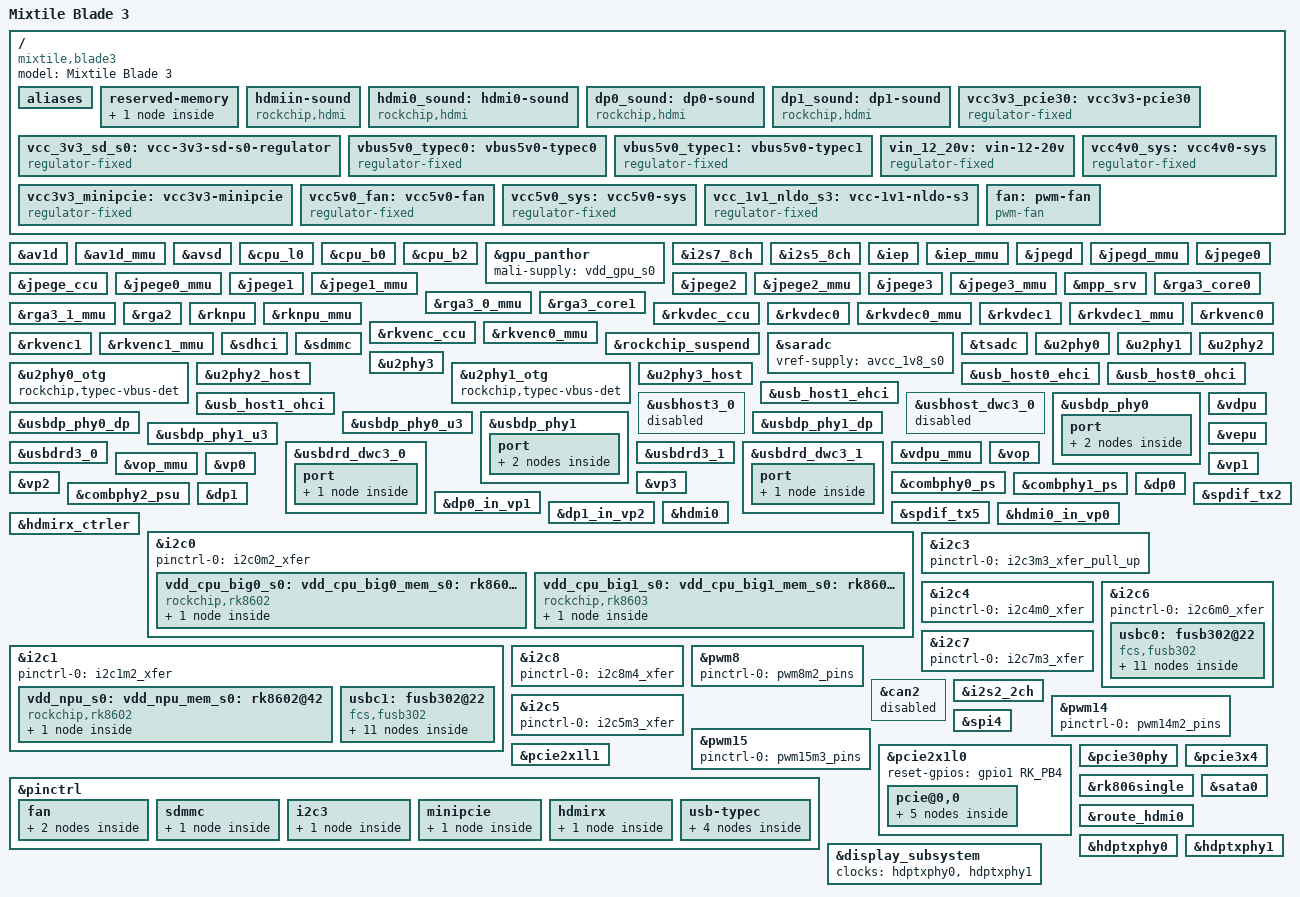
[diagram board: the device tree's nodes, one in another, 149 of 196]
// SPDX-License-Identifier: (GPL-2.0+ OR MIT)
/*
 * Copyright (c) 2026 Mixtile Limited
 *
 */

/dts-v1/;

#include <dt-bindings/gpio/gpio.h>
#include <dt-bindings/pwm/pwm.h>
#include <dt-bindings/pinctrl/rockchip.h>
#include <dt-bindings/input/rk-input.h>
#include <dt-bindings/display/drm_mipi_dsi.h>
#include <dt-bindings/display/rockchip_vop.h>
#include <dt-bindings/sensor-dev.h>

#include "dt-bindings/usb/pd.h"
#include "rk3588.dtsi"
#include "rk3588-rk806-single.dtsi"
#include "rk3588-linux.dtsi"

/ {
	model = "Mixtile Blade 3";
	compatible = "mixtile,blade3", "rockchip,rk3588";
	/delete-node/ chosen;

	aliases {
		ethernet0 = &rtl_eth0;
		ethernet1 = &rtl_eth1;
	};

	/* If hdmirx node is disabled, delete the reserved-memory node here. */
	reserved-memory {
		#address-cells = <2>;
		#size-cells = <2>;
		ranges;

		/* Reserve 256MB memory for hdmirx-controller@fdee0000 */
		cma {
			compatible = "shared-dma-pool";
			reusable;
			size = <0x0 (256 * 0x100000)>;
			linux,cma-default;
		};
	};

	hdmiin-sound {
		compatible = "rockchip,hdmi";
		rockchip,mclk-fs = <128>;
		rockchip,format = "i2s";
		rockchip,bitclock-master = <&hdmirx_ctrler>;
		rockchip,frame-master = <&hdmirx_ctrler>;
		rockchip,card-name = "rockchip-hdmiin";
		rockchip,cpu = <&i2s7_8ch>;
		rockchip,codec = <&hdmirx_ctrler 0>;
		rockchip,jack-det;
	};

	hdmi0_sound: hdmi0-sound {
		status = "okay";
		compatible = "rockchip,hdmi";
		rockchip,mclk-fs = <128>;
		rockchip,card-name = "rockchip-hdmi0";
		rockchip,cpu = <&i2s5_8ch>;
		rockchip,codec = <&hdmi0>;
		rockchip,jack-det;
	};

	dp0_sound: dp0-sound {
		status = "okay";
		compatible = "rockchip,hdmi";
		rockchip,card-name = "rockchip-dp0";
		rockchip,mclk-fs = <512>;
		rockchip,cpu = <&spdif_tx2>;
		rockchip,codec = <&dp0 1>;
		rockchip,jack-det;
	};

	dp1_sound: dp1-sound {
		status = "okay";
		compatible = "rockchip,hdmi";
		rockchip,card-name = "rockchip-dp1";
		rockchip,mclk-fs = <512>;
		rockchip,cpu = <&spdif_tx5>;
		rockchip,codec = <&dp1 1>;
		rockchip,jack-det;
	};

	vcc3v3_pcie30: vcc3v3-pcie30 {
		compatible = "regulator-fixed";
		regulator-name = "vcc3v3_pcie30";
		regulator-min-microvolt = <3300000>;
		regulator-max-microvolt = <3300000>;
		enable-active-high;
		gpio = <&gpio1 RK_PB2 GPIO_ACTIVE_HIGH>;
		startup-delay-us = <5000>;
		vin-supply = <&vcc4v0_sys>;
	};

	vcc_3v3_sd_s0: vcc-3v3-sd-s0-regulator {
		compatible = "regulator-fixed";
		regulator-name = "vcc_3v3_sd_s0";
		regulator-min-microvolt = <3300000>;
		regulator-max-microvolt = <3300000>;
		gpio = <&gpio0 RK_PB7 GPIO_ACTIVE_LOW>;
		startup-delay-us = <2000>;
		pinctrl-names = "default";
		pinctrl-0 = <&sd_s0_pwr>;
		vin-supply = <&vcc_3v3_s3>;
	};

	vbus5v0_typec0: vbus5v0-typec0 {
		compatible = "regulator-fixed";
		regulator-name = "vbus5v0_typec0";
		regulator-min-microvolt = <5000000>;
		regulator-max-microvolt = <5000000>;
		enable-active-high;
		gpio = <&gpio4 RK_PB0 GPIO_ACTIVE_HIGH>;
		pinctrl-names = "default";
		pinctrl-0 = <&typec5v_pwren0>;
		vin-supply = <&vcc5v0_sys>;
	};

	vbus5v0_typec1: vbus5v0-typec1 {
		compatible = "regulator-fixed";
		regulator-name = "vbus5v0_typec1";
		regulator-min-microvolt = <5000000>;
		regulator-max-microvolt = <5000000>;
		enable-active-high;
		gpio = <&gpio4 RK_PA3 GPIO_ACTIVE_HIGH>;
		pinctrl-names = "default";
		pinctrl-0 = <&typec5v_pwren1>;
		vin-supply = <&vcc5v0_sys>;
	};

	vin_12_20v: vin-12-20v {
		compatible = "regulator-fixed";
		regulator-name = "vin_12_20v";
		regulator-boot-on;
		regulator-always-on;
	};

	vcc4v0_sys: vcc4v0-sys {
		compatible = "regulator-fixed";
		regulator-name = "vcc4v0_sys";
		regulator-boot-on;
		regulator-always-on;
		regulator-min-microvolt = <4000000>;
		regulator-max-microvolt = <4000000>;
		vin-supply = <&vin_12_20v>;
	};

	vcc3v3_minipcie: vcc3v3-minipcie {
		compatible = "regulator-fixed";
		regulator-name = "vcc3v3_minipcie";
		regulator-boot-on;
		regulator-always-on;
		regulator-min-microvolt = <3300000>;
		regulator-max-microvolt = <3300000>;
		enable-active-high;
		gpio = <&gpio3 RK_PC6 GPIO_ACTIVE_HIGH>;
		startup-delay-us = <5000>;
		pinctrl-names = "default";
		pinctrl-0 = <&minipcie_pwren>;
		vin-supply = <&vin_12_20v>;
	};

	vcc5v0_fan: vcc5v0-fan {
		compatible = "regulator-fixed";
		regulator-name = "vcc5v0_fan";
		regulator-min-microvolt = <5000000>;
		regulator-max-microvolt = <5000000>;
		enable-active-high;
		gpio = <&gpio3 RK_PC0 GPIO_ACTIVE_HIGH>;
		pinctrl-names = "default";
		pinctrl-0 = <&fan_pwren>;
		vin-supply = <&vcc5v0_sys>;
	};

	vcc5v0_sys: vcc5v0-sys {
		compatible = "regulator-fixed";
		regulator-name = "vcc5v0_sys";
		regulator-boot-on;
		regulator-always-on;
		regulator-min-microvolt = <5000000>;
		regulator-max-microvolt = <5000000>;
		vin-supply = <&vin_12_20v>;
	};

	vcc_1v1_nldo_s3: vcc-1v1-nldo-s3 {
		compatible = "regulator-fixed";
		regulator-name = "vcc_1v1_nldo_s3";
		regulator-boot-on;
		regulator-always-on;
		regulator-min-microvolt = <1100000>;
		regulator-max-microvolt = <1100000>;
		vin-supply = <&vcc4v0_sys>;
	};

	fan: pwm-fan {
		compatible = "pwm-fan";
		interrupt-parent = <&gpio3>;
		interrupts = <RK_PB1 IRQ_TYPE_EDGE_FALLING>;
		pulses-per-revolution = <2>;
		#cooling-cells = <2>;
		cooling-levels = <0 35 70 100 125 150>;
		pwms = <&pwm8 0 40000 0>; /* 40000 meant for Noctua */
		pinctrl-names = "default";
		pinctrl-0 = <&fan_tach>; /* for the pull-up on the tacho input */
		fan-supply = <&vcc5v0_fan>;
		rockchip,temp-trips = <
			30000   1
			45000   2
			50000   3
			55000   4
			60000   5
		>;
	};
};

&av1d {
	status = "okay";
};

&av1d_mmu {
	status = "okay";
};

&avsd {
	status = "okay";
};

&cpu_l0 {
	cpu-supply = <&vdd_cpu_lit_s0>;
	mem-supply = <&vdd_cpu_lit_mem_s0>;
};

&cpu_b0 {
	cpu-supply = <&vdd_cpu_big0_s0>;
	mem-supply = <&vdd_cpu_big0_mem_s0>;
};

&cpu_b2 {
	cpu-supply = <&vdd_cpu_big1_s0>;
	mem-supply = <&vdd_cpu_big1_mem_s0>;
};

&gpu_panthor {
	mali-supply = <&vdd_gpu_s0>;
	status = "okay";
};

&i2s7_8ch {
	status = "okay";
};

&i2s5_8ch {
	status = "okay";
};

&iep {
	status = "okay";
};

&iep_mmu {
	status = "okay";
};

&jpegd {
	status = "okay";
};

&jpegd_mmu {
	status = "okay";
};

&jpege_ccu {
	status = "okay";
};

&jpege0 {
	status = "okay";
};

&jpege0_mmu {
	status = "okay";
};

&jpege1 {
	status = "okay";
};

&jpege1_mmu {
	status = "okay";
};

&jpege2 {
	status = "okay";
};

&jpege2_mmu {
	status = "okay";
};

&jpege3 {
	status = "okay";
};

&jpege3_mmu {
	status = "okay";
};

&mpp_srv {
	status = "okay";
};

&rga3_core0 {
	status = "okay";
};

&rga3_0_mmu {
	status = "okay";
};

&rga3_core1 {
	status = "okay";
};

&rga3_1_mmu {
	status = "okay";
};

&rga2 {
	status = "okay";
};

&rknpu {
	rknpu-supply = <&vdd_npu_s0>;
	mem-supply = <&vdd_npu_mem_s0>;
	status = "okay";
};

&rknpu_mmu {
	status = "okay";
};

&rkvdec_ccu {
	status = "okay";
};

&rkvdec0 {
	status = "okay";
};

&rkvdec0_mmu {
	status = "okay";
};

&rkvdec1 {
	status = "okay";
};

&rkvdec1_mmu {
	status = "okay";
};

&rkvenc_ccu {
	status = "okay";
};

&rkvenc0 {
	venc-supply = <&vdd_vdenc_s0>;
	mem-supply = <&vdd_vdenc_mem_s0>;
	status = "okay";
};

&rkvenc0_mmu {
	status = "okay";
};

&rkvenc1 {
	venc-supply = <&vdd_vdenc_s0>;
	mem-supply = <&vdd_vdenc_mem_s0>;
	status = "okay";
};

&rkvenc1_mmu {
	status = "okay";
};

&rockchip_suspend {
	status = "okay";
	rockchip,sleep-debug-en = <1>;
	rockchip,sleep-mode-config = <
		(0
		| RKPM_SLP_ARMOFF_DDRPD
		| RKPM_SLP_PMU_PMUALIVE_32K
		| RKPM_SLP_PMU_DIS_OSC
		)
	>;
};

&saradc {
	status = "okay";
	vref-supply = <&avcc_1v8_s0>;
};

&sdhci {
	bus-width = <8>;
	no-sdio;
	no-sd;
	non-removable;
	max-frequency = <200000000>;
	mmc-hs400-1_8v;
	mmc-hs400-enhanced-strobe;
	status = "okay";
};

&sdmmc {
	max-frequency = <150000000>;
	no-sdio;
	no-mmc;
	bus-width = <4>;
	cap-mmc-highspeed;
	cap-sd-highspeed;
	disable-wp;
	sd-uhs-sdr104;
	vmmc-supply = <&vcc_3v3_sd_s0>;
	vqmmc-supply = <&vccio_sd_s0>;
	status = "okay";
};

&tsadc {
	status = "okay";
};

&u2phy0 {
	status = "okay";
};

&u2phy1 {
	status = "okay";
};

&u2phy2 {
	status = "okay";
};

&u2phy3 {
	status = "okay";
};

&u2phy0_otg {
	status = "okay";
	rockchip,typec-vbus-det;
};

&u2phy1_otg {
	status = "okay";
	rockchip,typec-vbus-det;
};

&u2phy2_host {
	status = "okay";
};

&u2phy3_host {
	status = "okay";
};

&usb_host0_ehci {
	status = "okay";
};

&usb_host0_ohci {
	status = "okay";
};

&usb_host1_ehci {
	status = "okay";
};

&usb_host1_ohci {
	status = "okay";
};

&usbhost3_0 {
	status = "disabled";
};

&usbhost_dwc3_0 {
	status = "disabled";
};

&usbdp_phy0 {
	status = "okay";

	orientation-switch;
	svid = <0xff01>;
	sbu1-dc-gpios = <&gpio4 RK_PA6 GPIO_ACTIVE_HIGH>;
	sbu2-dc-gpios = <&gpio4 RK_PA7 GPIO_ACTIVE_HIGH>;

	port {
		#address-cells = <1>;
		#size-cells = <0>;
		usbdp_phy0_orientation_switch: endpoint@0 {
			reg = <0>;
			remote-endpoint = <&usbc0_orien_sw>;
		};

		usbdp_phy0_dp_altmode_mux: endpoint@1 {
			reg = <1>;
			remote-endpoint = <&dp0_altmode_mux>;
		};
	};
};

&usbdp_phy0_dp {
	status = "okay";
};

&usbdp_phy0_u3 {
	status = "okay";
};

&usbdp_phy1 {
	status = "okay";

	orientation-switch;
	svid = <0xff01>;
	sbu1-dc-gpios = <&gpio4 RK_PA4 GPIO_ACTIVE_HIGH>;
	sbu2-dc-gpios = <&gpio4 RK_PA5 GPIO_ACTIVE_HIGH>;

	port {
		#address-cells = <1>;
		#size-cells = <0>;
		usbdp_phy1_orientation_switch: endpoint@0 {
			reg = <0>;
			remote-endpoint = <&usbc1_orien_sw>;
		};

		usbdp_phy1_dp_altmode_mux: endpoint@1 {
			reg = <1>;
			remote-endpoint = <&dp1_altmode_mux>;
		};
	};
};

&usbdp_phy1_dp {
	status = "okay";
};

&usbdp_phy1_u3 {
	status = "okay";
};

&usbdrd3_0 {
	status = "okay";
};

&usbdrd_dwc3_0 {
	status = "okay";

	dr_mode = "otg";
	usb-role-switch;
	port {
		#address-cells = <1>;
		#size-cells = <0>;
		dwc3_0_role_switch: endpoint@0 {
			reg = <0>;
			remote-endpoint = <&usbc0_role_sw>;
		};
	};
};

&usbdrd3_1 {
	status = "okay";
};

&usbdrd_dwc3_1 {
	status = "okay";

	dr_mode = "otg";
	usb-role-switch;
	port {
		#address-cells = <1>;
		#size-cells = <0>;
		dwc3_1_role_switch: endpoint@0 {
			reg = <0>;
			remote-endpoint = <&usbc1_role_sw>;
		};
	};
};

&vdpu {
	status = "okay";
};

&vdpu_mmu {
	status = "okay";
};

&vepu {
	status = "okay";
};

&vop {
	assigned-clocks = <&cru ACLK_VOP>;
	assigned-clock-rates = <800000000>;
	vop-supply = <&vdd_log_s0>;
	status = "okay";
};

&vop_mmu {
	status = "okay";
};

/* vp0 & vp1 splice for 8K output */
&vp0 {
	rockchip,plane-mask = <(1 << ROCKCHIP_VOP2_CLUSTER0 | 1 << ROCKCHIP_VOP2_ESMART0)>;
	rockchip,primary-plane = <ROCKCHIP_VOP2_CLUSTER0>;
	cursor-win-id = <ROCKCHIP_VOP2_ESMART0>;
};

&vp1 {
	rockchip,plane-mask = <(1 << ROCKCHIP_VOP2_CLUSTER1 | 1 << ROCKCHIP_VOP2_ESMART1)>;
	rockchip,primary-plane = <ROCKCHIP_VOP2_CLUSTER1>;
	cursor-win-id = <ROCKCHIP_VOP2_ESMART1>;
};

&vp2 {
	rockchip,plane-mask = <(1 << ROCKCHIP_VOP2_CLUSTER2 | 1 << ROCKCHIP_VOP2_ESMART2)>;
	rockchip,primary-plane = <ROCKCHIP_VOP2_CLUSTER2>;
	cursor-win-id = <ROCKCHIP_VOP2_ESMART2>;
};

&vp3 {
	rockchip,plane-mask = <(1 << ROCKCHIP_VOP2_CLUSTER3 | 1 << ROCKCHIP_VOP2_ESMART3)>;
	rockchip,primary-plane = <ROCKCHIP_VOP2_CLUSTER3>;
	cursor-win-id = <ROCKCHIP_VOP2_ESMART3>;
};

&combphy0_ps {
	status = "okay";
};

&combphy1_ps {
	status = "okay";
};

&combphy2_psu {
	status = "okay";
};

&dp0 {
	status = "okay";
};

&dp0_in_vp1 {
	status = "okay";
};

&spdif_tx2 {
	status = "okay";
};

&dp1 {
	status = "okay";
};

&dp1_in_vp2 {
	status = "okay";
};

&spdif_tx5 {
	status = "okay";
};

&hdmi0 {
	enable-gpios = <&gpio4 RK_PB1 GPIO_ACTIVE_HIGH>;
	cec-enable;
	status = "okay";
};

&hdmi0_in_vp0 {
	status = "okay";
};

/* Should work with at least 128MB cma reserved above. */
&hdmirx_ctrler {
	status = "okay";
	#sound-dai-cells = <1>;
	/* Effective level used to trigger HPD: 0-low, 1-high */
	hpd-trigger-level = <1>;
	hdmirx-det-gpios = <&gpio1 RK_PD5 GPIO_ACTIVE_LOW>;
	pinctrl-0 = <&hdmim1_rx_cec &hdmim1_rx_hpdin &hdmim1_rx_scl &hdmim1_rx_sda &hdmirx_det>;
	pinctrl-names = "default";
};

&i2c0 {
	status = "okay";
	pinctrl-names = "default";
	pinctrl-0 = <&i2c0m2_xfer>;

	vdd_cpu_big0_s0: vdd_cpu_big0_mem_s0: rk8602@42 {
		compatible = "rockchip,rk8602";
		reg = <0x42>;
		vin-supply = <&vcc4v0_sys>;
		regulator-compatible = "rk860x-reg";
		regulator-name = "vdd_cpu_big0_s0";
		regulator-min-microvolt = <550000>;
		regulator-max-microvolt = <1050000>;
		regulator-ramp-delay = <2300>;
		rockchip,suspend-voltage-selector = <1>;
		regulator-boot-on;
		regulator-always-on;
		regulator-state-mem {
			regulator-off-in-suspend;
		};
	};

	vdd_cpu_big1_s0: vdd_cpu_big1_mem_s0: rk8603@43 {
		compatible = "rockchip,rk8603";
		reg = <0x43>;
		vin-supply = <&vcc4v0_sys>;
		regulator-compatible = "rk860x-reg";
		regulator-name = "vdd_cpu_big1_s0";
		regulator-min-microvolt = <550000>;
		regulator-max-microvolt = <1050000>;
		regulator-ramp-delay = <2300>;
		rockchip,suspend-voltage-selector = <1>;
		regulator-boot-on;
		regulator-always-on;
		regulator-state-mem {
			regulator-off-in-suspend;
		};
	};
};

&i2c1 {
	status = "okay";
	pinctrl-names = "default";
	pinctrl-0 = <&i2c1m2_xfer>;

	vdd_npu_s0: vdd_npu_mem_s0: rk8602@42 {
		compatible = "rockchip,rk8602";
		reg = <0x42>;
		vin-supply = <&vcc4v0_sys>;
		regulator-compatible = "rk860x-reg";
		regulator-name = "vdd_npu_s0";
		regulator-min-microvolt = <550000>;
		regulator-max-microvolt = <950000>;
		regulator-ramp-delay = <2300>;
		rockchip,suspend-voltage-selector = <1>;
		regulator-boot-on;
		regulator-always-on;
		regulator-state-mem {
			regulator-off-in-suspend;
		};
	};

	usbc1: fusb302@22 {
		compatible = "fcs,fusb302";
		reg = <0x22>;
		interrupt-parent = <&gpio0>;
		interrupts = <RK_PC6 IRQ_TYPE_LEVEL_LOW>;
		pinctrl-names = "default";
		pinctrl-0 = <&usbc1_int>;
		vbus-supply = <&vbus5v0_typec1>;
		status = "okay";

		ports {
			#address-cells = <1>;
			#size-cells = <0>;

			port@0 {
				reg = <0>;
				usbc1_role_sw: endpoint@0 {
					remote-endpoint = <&dwc3_1_role_switch>;
				};
			};
		};

		usb_con1: connector {
			compatible = "usb-c-connector";
			label = "USB-C";
			data-role = "dual";
			power-role = "dual";
			try-power-role = "sink";
			faster-pd-negotiation;
			op-sink-microwatt = <15000000>;
			sink-pdos =
				<PDO_FIXED(5000, 1000, PDO_FIXED_USB_COMM)
				PDO_VAR(5000, 20000, 1000)
				PDO_PPS_APDO(5000, 20000, 1000)>;
			source-pdos =
				<PDO_FIXED(5000, 1000, PDO_FIXED_USB_COMM)>;

			altmodes {
				#address-cells = <1>;
				#size-cells = <0>;

				altmode@0 {
					reg = <0>;
					svid = <0xff01>;
					vdo = <0xffffffff>;
				};
			};

			ports {
				#address-cells = <1>;
				#size-cells = <0>;

				port@0 {
					reg = <0>;
					usbc1_orien_sw: endpoint {
						remote-endpoint = <&usbdp_phy1_orientation_switch>;
					};
				};

				port@1 {
					reg = <1>;
					dp1_altmode_mux: endpoint {
						remote-endpoint = <&usbdp_phy1_dp_altmode_mux>;
					};
				};
			};
		};
	};
};

&i2c3 {
	status = "okay";
	pinctrl-0 = <&i2c3m3_xfer_pull_up>;
};

&i2c4 {
	status = "okay";
	pinctrl-0 = <&i2c4m0_xfer>;
};

&i2c6 {
	status = "okay";
	pinctrl-0 = <&i2c6m0_xfer>;

	usbc0: fusb302@22 {
		compatible = "fcs,fusb302";
		reg = <0x22>;
		interrupt-parent = <&gpio0>;
		interrupts = <RK_PC5 IRQ_TYPE_LEVEL_LOW>;
		pinctrl-names = "default";
		pinctrl-0 = <&usbc0_int>;
		vbus-supply = <&vbus5v0_typec0>;
		status = "okay";

		ports {
			#address-cells = <1>;
			#size-cells = <0>;

			port@0 {
				reg = <0>;
				usbc0_role_sw: endpoint@0 {
					remote-endpoint = <&dwc3_0_role_switch>;
				};
			};
		};

		usb_con0: connector {
			compatible = "usb-c-connector";
			label = "USB-C";
			data-role = "dual";
			power-role = "dual";
			try-power-role = "sink";
			op-sink-microwatt = <1000000>;
			sink-pdos =
				<PDO_FIXED(5000, 1000, PDO_FIXED_USB_COMM)>;
			source-pdos =
				<PDO_FIXED(5000, 1000, PDO_FIXED_USB_COMM)>;

			altmodes {
				#address-cells = <1>;
				#size-cells = <0>;

				altmode@0 {
					reg = <0>;
					svid = <0xff01>;
					vdo = <0xffffffff>;
				};
			};

			ports {
				#address-cells = <1>;
				#size-cells = <0>;

				port@0 {
					reg = <0>;
					usbc0_orien_sw: endpoint {
						remote-endpoint = <&usbdp_phy0_orientation_switch>;
					};
				};

				port@1 {
					reg = <1>;
					dp0_altmode_mux: endpoint {
						remote-endpoint = <&usbdp_phy0_dp_altmode_mux>;
					};
				};
			};
		};
	};
};

&i2c7 {
	status = "okay";
	pinctrl-0 = <&i2c7m3_xfer>;
};

&i2c8 {
	status = "okay";
	pinctrl-0 = <&i2c8m4_xfer>;
};

&pwm8 {
	status = "okay";
	pinctrl-0 = <&pwm8m2_pins>;
};

&can2 {
	status = "disabled";
};

&i2c5 {
	status = "okay";
	pinctrl-0 = <&i2c5m3_xfer>;
};

&i2s2_2ch {
	status = "okay";
	pinctrl-names = "default";
	pinctrl-0 = <&i2s2m1_mclk
		     &i2s2m1_lrck
		     &i2s2m1_sclk
		     &i2s2m1_sdi
		     &i2s2m1_sdo>;
};

&pwm14 {
	status = "okay";
	pinctrl-0 = <&pwm14m2_pins>;
};

&pwm15 {
	status = "okay";
	pinctrl-0 = <&pwm15m3_pins>;
};

&spi4 {
	status = "okay";
	pinctrl-names = "default";
	pinctrl-0 = <&spi4m2_cs0 &spi4m2_pins>;
	num-cs = <1>;
};

&pcie2x1l0 {
	reset-gpios = <&gpio1 RK_PB4 GPIO_ACTIVE_HIGH>;
	status = "okay";

	/*
	 * Describe the fixed PCIe topology on this port so the two soldered
	 * RTL8125 2.5GbE controllers get stable ethernet0/ethernet1 aliases and
	 * can take a fixed/nvmem MAC. Mirrors the enumerated hierarchy (domain
	 * 0002 in lspci):
	 *   20:00.0 RK3588 root port
	 *     21:00.0 ASM1182e switch upstream
	 *       22:03.0 downstream port -> 23:00.0 RTL8125 #0 (eth0)
	 *       22:07.0 downstream port -> 24:00.0 RTL8125 #1 (eth1)
	 * reg encodes the config address (bus << 16 | dev << 11 | fn << 8).
	 */
	pcie@0,0 {
		reg = <0x200000 0 0 0 0>;
		#address-cells = <3>;
		#size-cells = <2>;
		ranges;
		device_type = "pci";
		bus-range = <0x20 0x2f>;

		pcie@0,0 { // ASM1182e switch upstream port (21:00.0)
			reg = <0x210000 0 0 0 0>;
			#address-cells = <3>;
			#size-cells = <2>;
			ranges;
			device_type = "pci";
			bus-range = <0x22 0x24>;

			pcie@3,0 { // ASM1182e downstream port (22:03.0)
				reg = <0x221800 0 0 0 0>;
				#address-cells = <3>;
				#size-cells = <2>;
				ranges;
				device_type = "pci";
				bus-range = <0x23 0x23>;

				rtl_eth0: ethernet@0,0 { // RTL8125 #0 (23:00.0)
					compatible = "pci10ec,8125";
					reg = <0x230000 0 0 0 0>;
				};
			};

			pcie@7,0 { // ASM1182e downstream port (22:07.0)
				reg = <0x223800 0 0 0 0>;
				#address-cells = <3>;
				#size-cells = <2>;
				ranges;
				device_type = "pci";
				bus-range = <0x24 0x24>;

				rtl_eth1: ethernet@0,0 { // RTL8125 #1 (24:00.0)
					compatible = "pci10ec,8125";
					reg = <0x240000 0 0 0 0>;
				};
			};
		};
	};
};

&pcie2x1l1 {
	reset-gpios = <&gpio4 RK_PA2 GPIO_ACTIVE_HIGH>;
	vpcie3v3-supply = <&vcc3v3_minipcie>;
	status = "okay";
};

&pcie30phy {
	rockchip,pcie30-phymode = <PHY_MODE_PCIE_AGGREGATION>;
	status = "okay";
};

&pcie3x4 {
	reset-gpios = <&gpio4 RK_PB6 GPIO_ACTIVE_HIGH>;
	vpcie3v3-supply = <&vcc3v3_pcie30>;
	status = "okay";
};

&pinctrl {
	fan {
		fan_tach: fan-tach {
			rockchip,pins = <3 RK_PB1 RK_FUNC_GPIO &pcfg_pull_up>;
		};

		fan_pwren: fan-pwren {
			rockchip,pins = <3 RK_PC0 RK_FUNC_GPIO &pcfg_pull_none>;
		};
	};

	sdmmc {
		sd_s0_pwr: sd-s0-pwr {
			rockchip,pins = <0 RK_PB7 RK_FUNC_GPIO &pcfg_pull_up>;
		};
	};

	i2c3 {
		i2c3m3_xfer_pull_up: i2c3m3-xfer-pull-up {
			rockchip,pins = <2 RK_PB2 9 &pcfg_pull_up_smt>,
					<2 RK_PB3 9 &pcfg_pull_up_smt>;
		};
	};

	minipcie {
		minipcie_pwren: minipcie-pwren {
			rockchip,pins = <3 RK_PC6 RK_FUNC_GPIO &pcfg_pull_none>;
		};
	};

	hdmirx {
		hdmirx_det: hdmirx-det {
			rockchip,pins = <1 RK_PD5 RK_FUNC_GPIO &pcfg_pull_none>;
		};
	};

	usb-typec {
		usbc0_int: usbc0-int {
			rockchip,pins = <0 RK_PC5 RK_FUNC_GPIO &pcfg_pull_up>;
		};

		usbc1_int: usbc1-int {
			rockchip,pins = <0 RK_PC6 RK_FUNC_GPIO &pcfg_pull_up>;
		};

		typec5v_pwren0: typec5v-pwren0 {
			rockchip,pins = <4 RK_PB0 RK_FUNC_GPIO &pcfg_pull_none>;
		};

		typec5v_pwren1: typec5v-pwren1 {
			rockchip,pins = <4 RK_PA3 RK_FUNC_GPIO &pcfg_pull_none>;
		};
	};
};

&rk806single {
	vcc1-supply = <&vcc4v0_sys>;
	vcc2-supply = <&vcc4v0_sys>;
	vcc3-supply = <&vcc4v0_sys>;
	vcc4-supply = <&vcc4v0_sys>;
	vcc5-supply = <&vcc4v0_sys>;
	vcc6-supply = <&vcc4v0_sys>;
	vcc7-supply = <&vcc4v0_sys>;
	vcc8-supply = <&vcc4v0_sys>;
	vcc9-supply = <&vcc4v0_sys>;
	vcc10-supply = <&vcc4v0_sys>;
	vcc12-supply = <&vcc4v0_sys>;
	vcca-supply = <&vcc4v0_sys>;
};

&route_hdmi0 {
	status = "okay";
};

&sata0 {
	status = "okay";
};

&hdptxphy0 {
	status = "okay";
};

&hdptxphy1 {
	status = "okay";
};

&display_subsystem {
	clocks = <&hdptxphy0>, <&hdptxphy1>;
	clock-names = "hdmi0_phy_pll", "hdmi1_phy_pll";
};
